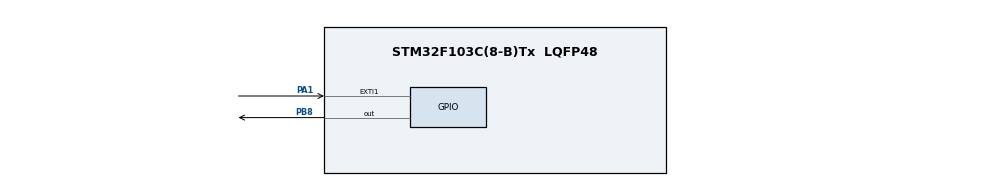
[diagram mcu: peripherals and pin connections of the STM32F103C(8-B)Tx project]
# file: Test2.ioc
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Mcu.Family=STM32F1
Mcu.Name=STM32F103C(8-B)Tx
Mcu.Package=LQFP48
NVIC.EXTI1_IRQn=true\:0\:0\:false\:false\:true\:true\:true\:true
NVIC.PriorityGroup=NVIC_PRIORITYGROUP_4
PA1.GPIO_PuPd=GPIO_PULLUP
PA1.Signal=GPXTI1
PA13.Mode=Serial_Wire
PA13.Signal=SYS_JTMS-SWDIO
PA14.Mode=Serial_Wire
PA14.Signal=SYS_JTCK-SWCLK
PB8.Signal=GPIO_Output
PD0-OSC_IN.Mode=HSE-External-Oscillator
PD0-OSC_IN.Signal=RCC_OSC_IN
PD1-OSC_OUT.Mode=HSE-External-Oscillator
PD1-OSC_OUT.Signal=RCC_OSC_OUT
ProjectManager.HeapSize=0x200
ProjectManager.StackSize=0x400
ProjectManager.TargetToolchain=STM32CubeIDE
RCC.APB1Freq_Value=8000000
RCC.APB2Freq_Value=8000000
board=custom

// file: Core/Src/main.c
/* USER CODE BEGIN Header */
/**
  ******************************************************************************
  * @file           : main.c
  * @brief          : Main program body
  ******************************************************************************
  * @attention
  *
  * Copyright (c) 2026 STMicroelectronics.
  * All rights reserved.
  *
  * This software is licensed under terms that can be found in the LICENSE file
  * in the root directory of this software component.
  * If no LICENSE file comes with this software, it is provided AS-IS.
  *
  ******************************************************************************
  */
/* USER CODE END Header */
#include "main.h"

/* USER CODE BEGIN PV */
volatile uint32_t count1 =0u;
/* USER CODE END PV */

void SystemClock_Config(void);
static void MX_GPIO_Init(void);
/* USER CODE BEGIN PFP */
static void button(void);
static void blink_led(int reverse);
/* USER CODE END PFP */

/* USER CODE BEGIN 0 */
// led config
typedef struct {
	GPIO_TypeDef *Port;
	uint16_t Pin;
}Led_Config;

Led_Config listLed[] = {
	{GPIOB,GPIO_PIN_8},
	{GPIOA,GPIO_PIN_8},
	{GPIOC,GPIO_PIN_13}
};
static uint32_t last_interrupt_time = 0;
/* USER CODE END 0 */

int main(void)
{

  /* MCU Configuration--------------------------------------------------------*/

  /* Reset of all peripherals, Initializes the Flash interface and the Systick. */
  HAL_Init();

  /* Configure the system clock */
  SystemClock_Config();

  /* Initialize all configured peripherals */
  MX_GPIO_Init();

  /* Infinite loop */
  /* USER CODE BEGIN WHILE */
  while (1)
  {
	  //button();
	  if (count1%2 == 0)
		  blink_led(0);
	  else
		  blink_led(1);
    /* USER CODE END WHILE */

  }
}

void SystemClock_Config(void)
{
  RCC_OscInitTypeDef RCC_OscInitStruct = {0};
  RCC_ClkInitTypeDef RCC_ClkInitStruct = {0};

  /** Initializes the RCC Oscillators according to the specified parameters
  * in the RCC_OscInitTypeDef structure.
  */
  RCC_OscInitStruct.OscillatorType = RCC_OSCILLATORTYPE_HSI;
  RCC_OscInitStruct.HSIState = RCC_HSI_ON;
  RCC_OscInitStruct.HSICalibrationValue = RCC_HSICALIBRATION_DEFAULT;
  RCC_OscInitStruct.PLL.PLLState = RCC_PLL_NONE;
  if (HAL_RCC_OscConfig(&RCC_OscInitStruct) != HAL_OK)
  {
    Error_Handler();
  }

  /** Initializes the CPU, AHB and APB buses clocks
  */
  RCC_ClkInitStruct.ClockType = RCC_CLOCKTYPE_HCLK|RCC_CLOCKTYPE_SYSCLK
                              |RCC_CLOCKTYPE_PCLK1|RCC_CLOCKTYPE_PCLK2;
  RCC_ClkInitStruct.SYSCLKSource = RCC_SYSCLKSOURCE_HSI;
  RCC_ClkInitStruct.AHBCLKDivider = RCC_SYSCLK_DIV1;
  RCC_ClkInitStruct.APB1CLKDivider = RCC_HCLK_DIV1;
  RCC_ClkInitStruct.APB2CLKDivider = RCC_HCLK_DIV1;

  if (HAL_RCC_ClockConfig(&RCC_ClkInitStruct, FLASH_LATENCY_0) != HAL_OK)
  {
    Error_Handler();
  }
}

static void MX_GPIO_Init(void)
{
  GPIO_InitTypeDef GPIO_InitStruct = {0};

  /* GPIO Ports Clock Enable */
  __HAL_RCC_GPIOD_CLK_ENABLE();
  __HAL_RCC_GPIOA_CLK_ENABLE();
  __HAL_RCC_GPIOB_CLK_ENABLE();

  /*Configure GPIO pin Output Level */
  HAL_GPIO_WritePin(GPIOB, GPIO_PIN_8, GPIO_PIN_RESET);

  /*Configure GPIO pin : PA1 */
  GPIO_InitStruct.Pin = GPIO_PIN_1;
  GPIO_InitStruct.Mode = GPIO_MODE_IT_RISING;
  GPIO_InitStruct.Pull = GPIO_PULLUP;
  HAL_GPIO_Init(GPIOA, &GPIO_InitStruct);

  /*Configure GPIO pin : PB8 */
  GPIO_InitStruct.Pin = GPIO_PIN_8;
  GPIO_InitStruct.Mode = GPIO_MODE_OUTPUT_PP;
  GPIO_InitStruct.Pull = GPIO_NOPULL;
  GPIO_InitStruct.Speed = GPIO_SPEED_FREQ_LOW;
  HAL_GPIO_Init(GPIOB, &GPIO_InitStruct);

  /* EXTI interrupt init*/
  HAL_NVIC_SetPriority(EXTI1_IRQn, 0, 0);
  HAL_NVIC_EnableIRQ(EXTI1_IRQn);

  /* USER CODE BEGIN MX_GPIO_Init_2 */
  	/*Configure GPIO pin Output Level */
	HAL_GPIO_WritePin(GPIOB, GPIO_PIN_8, GPIO_PIN_RESET);

	/*Configure GPIO pin : PB1 */
	GPIO_InitStruct.Pin = GPIO_PIN_1;
	GPIO_InitStruct.Mode = GPIO_MODE_INPUT;
	GPIO_InitStruct.Pull = GPIO_PULLUP;
	HAL_GPIO_Init(GPIOB, &GPIO_InitStruct);

	GPIO_InitTypeDef GPIO_ConfigStruct = {0};
	/*Configure GPIO pin Output Level */
	HAL_GPIO_WritePin(GPIOA, GPIO_PIN_8, GPIO_PIN_RESET);
	/*Configure GPIO pin Output Level */
	HAL_GPIO_WritePin(GPIOC, GPIO_PIN_13, GPIO_PIN_RESET);

	/*Configure GPIO pin : PA8 */
	GPIO_ConfigStruct.Pin = GPIO_PIN_8;
	GPIO_ConfigStruct.Mode = GPIO_MODE_OUTPUT_PP;
	GPIO_ConfigStruct.Pull = GPIO_NOPULL;
	GPIO_ConfigStruct.Speed = GPIO_SPEED_FREQ_LOW;
	HAL_GPIO_Init(GPIOA, &GPIO_ConfigStruct);

	/*Configure GPIO pin : PC13 */
	__HAL_RCC_GPIOC_CLK_ENABLE();
	GPIO_ConfigStruct.Pin = GPIO_PIN_13;
	GPIO_ConfigStruct.Mode = GPIO_MODE_OUTPUT_PP;
	GPIO_ConfigStruct.Pull = GPIO_NOPULL;
	GPIO_ConfigStruct.Speed = GPIO_SPEED_FREQ_LOW;
	HAL_GPIO_Init(GPIOC, &GPIO_ConfigStruct);
  /* USER CODE END MX_GPIO_Init_2 */
}

/* USER CODE BEGIN 4 */

/**
  * @brief practice button
  */
static void button(void)
{

	if (HAL_GPIO_ReadPin(GPIOA,GPIO_PIN_1)==0U)
	{
		HAL_Delay(20);
		if (HAL_GPIO_ReadPin(GPIOA,GPIO_PIN_1)==0U)
		{
			count1++;
			HAL_GPIO_TogglePin(GPIOB,GPIO_PIN_8);
			while(HAL_GPIO_ReadPin(GPIOA,GPIO_PIN_1)==0U);
		}
	}

}

/**
  * @brief practice blink led
  */
static void blink_led(int reverse)
{
	/* blink led */
//	GPIOB->BSRR = GPIO_PIN_8;
//	HAL_Delay(500);
//	GPIOB->BSRR = (GPIO_PIN_8<<16);
//	HAL_Delay(500);
//	GPIOA->BSRR = GPIO_PIN_8;
//	HAL_Delay(500);
//	GPIOA->BSRR = (GPIO_PIN_8<<16);
//	HAL_Delay(500);
//	GPIOC->BSRR = GPIO_PIN_13;
//	HAL_Delay(500);
//	GPIOC->BSRR = (GPIO_PIN_13<<16);
//	HAL_Delay(500);
	if (!reverse)
	{
		for(int i=0;i<3;i++)
		{
			listLed[i].Port->BSRR = listLed[i].Pin;
			HAL_Delay(500);
			listLed[i].Port->BSRR = (listLed[i].Pin <<16);
			HAL_Delay(500);
		}
	}
	else
	{
		for(int i=2;i>=0;i--)
		{
			listLed[i].Port->BSRR = listLed[i].Pin;
			HAL_Delay(500);
			listLed[i].Port->BSRR = (listLed[i].Pin <<16);
			HAL_Delay(500);
		}
	}
}

/**
  * @brief practice external interrupt
  */
void HAL_GPIO_EXTI_Callback(uint16_t GPIO_Pin)
{
	if(GPIO_Pin == GPIO_PIN_1) // Kiểm tra xem có đúng là chân PA1 kích hoạt ngắt không
	{
		//static uint32_t last_interrupt_time = 0;
		uint32_t current_time = HAL_GetTick();
		if (current_time - last_interrupt_time >200)
		{
			count1++; // Tăng biến đếm
			last_interrupt_time = current_time;
		}
	}
}
/* USER CODE END 4 */

void Error_Handler(void)
{
  __disable_irq();
  while (1)
  {
  }
}
